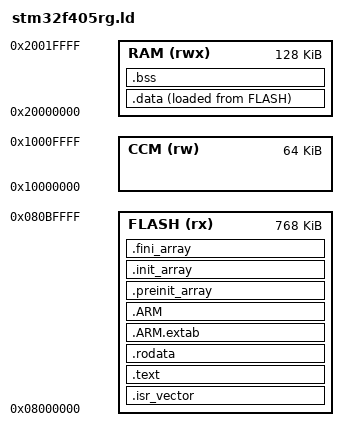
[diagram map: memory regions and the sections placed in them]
/* STM32F405RG — 1MB 플래시 중 섹터 0~9(768KB)만 프로그램. 섹터 10·11은 설정 기록(cfgstore) 자리.
   스택은 CCM 64KB 통째(꼭대기에서 아래로, 바닥 32B는 MPU 보호 구역). 데이터·DMA 버퍼는 SRAM 128KB. */
ENTRY(Reset_Handler)

MEMORY
{
  FLASH (rx)  : ORIGIN = 0x08000000, LENGTH = 768K
  RAM   (rwx) : ORIGIN = 0x20000000, LENGTH = 128K
  CCM   (rw)  : ORIGIN = 0x10000000, LENGTH = 64K
}

_estack = ORIGIN(CCM) + LENGTH(CCM);

SECTIONS
{
  .isr_vector : { . = ALIGN(4); KEEP(*(.isr_vector)) . = ALIGN(4); } > FLASH

  .text :
  {
    . = ALIGN(4);
    *(.text) *(.text*) *(.glue_7) *(.glue_7t) *(.eh_frame)
    KEEP(*(.init)) KEEP(*(.fini))
    . = ALIGN(4);
    _etext = .;
  } > FLASH

  .rodata : { . = ALIGN(4); *(.rodata) *(.rodata*) . = ALIGN(4); } > FLASH
  .ARM.extab : { *(.ARM.extab* .gnu.linkonce.armextab.*) } > FLASH
  .ARM : { __exidx_start = .; *(.ARM.exidx*) __exidx_end = .; } > FLASH

  .preinit_array : { PROVIDE_HIDDEN(__preinit_array_start = .); KEEP(*(.preinit_array*)) PROVIDE_HIDDEN(__preinit_array_end = .); } > FLASH
  .init_array : { PROVIDE_HIDDEN(__init_array_start = .); KEEP(*(SORT(.init_array.*))) KEEP(*(.init_array*)) PROVIDE_HIDDEN(__init_array_end = .); } > FLASH
  .fini_array : { PROVIDE_HIDDEN(__fini_array_start = .); KEEP(*(SORT(.fini_array.*))) KEEP(*(.fini_array*)) PROVIDE_HIDDEN(__fini_array_end = .); } > FLASH

  _sidata = LOADADDR(.data);
  .data :
  {
    . = ALIGN(4);
    _sdata = .;
    *(.data) *(.data*)
    . = ALIGN(4);
    _edata = .;
  } > RAM AT> FLASH

  .bss (NOLOAD) :
  {
    . = ALIGN(4);
    _sbss = .;
    __bss_start__ = _sbss;
    *(.bss) *(.bss*) *(COMMON)
    . = ALIGN(4);
    _ebss = .;
    __bss_end__ = _ebss;
  } > RAM

  /* 힙은 없다(malloc 금지). newlib이 찾는 기호만 둔다. */
  PROVIDE(end = _ebss);
  PROVIDE(_end = _ebss);

  .ARM.attributes 0 : { *(.ARM.attributes) }
}

ASSERT(_etext <= 0x080C0000, "펌웨어가 설정 섹터(10)까지 넘쳤다")
